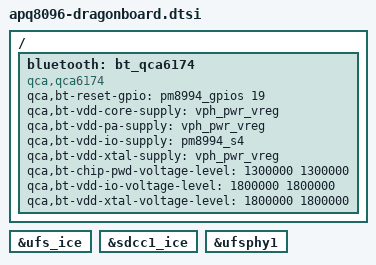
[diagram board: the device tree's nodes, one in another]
#include "msm8996-pinctrl.dtsi"
#include "apq8096-camera-sensor-dragonboard.dtsi"
#include "apq8096-ba.dtsi"

/ {
  bluetooth: bt_qca6174 {		compatible = "qca,qca6174";
  qca,bt-reset-gpio = <&pm8994_gpios 19 0>; /* BT_EN */
  qca,bt-vdd-core-supply = <&vph_pwr_vreg>;
  qca,bt-vdd-pa-supply = <&vph_pwr_vreg>;
  qca,bt-vdd-io-supply = <&pm8994_s4>;
  qca,bt-vdd-xtal-supply = <&vph_pwr_vreg>;
  qca,bt-chip-pwd-voltage-level = <1300000 1300000>;
  qca,bt-vdd-io-voltage-level = <1800000 1800000>;
  qca,bt-vdd-xtal-voltage-level = <1800000 1800000>;
  };
};

&ufs_ice {
  status = "ok";
};

&sdcc1_ice {
  status = "ok";
};

&ufsphy1 {
  status = "ok";
};
